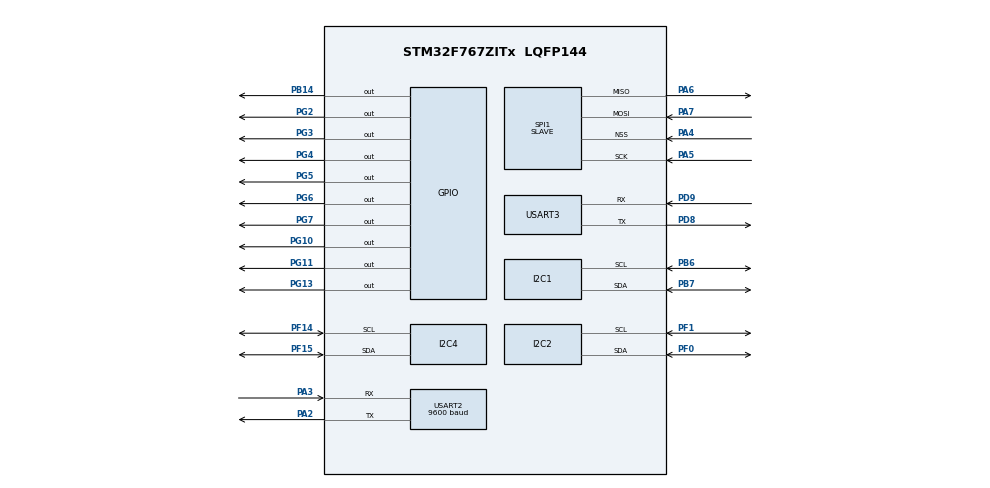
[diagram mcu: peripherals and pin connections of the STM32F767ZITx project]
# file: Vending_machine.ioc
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Mcu.Family=STM32F7
PA6.Mode=Full_Duplex_Slave
Dma.SPI1_TX.0.MemInc=DMA_MINC_ENABLE
Dma.SPI1_TX.0.PeriphInc=DMA_PINC_DISABLE
Dma.SPI1_RX.1.Mode=DMA_CIRCULAR
PG6.Signal=GPIO_Output
Dma.SPI1_RX.1.FIFOMode=DMA_FIFOMODE_DISABLE
NVIC.I2C1_EV_IRQn=true\:0\:0\:false\:false\:true\:true\:true
SPI1.VirtualType=VM_SLAVE
Dma.I2C1_TX.2.PeriphDataAlignment=DMA_PDATAALIGN_BYTE
PG2.Signal=GPIO_Output
PG4.Signal=GPIO_Output
PB7.GPIO_FM7=__NULL
PC14/OSC32_IN.Mode=LSE-External-Oscillator
PG13.Signal=GPIO_Output
PD9.Mode=Asynchronous
PG11.Signal=GPIO_Output
ProjectManager.StackSize=0x400
USART3.VirtualMode-Asynchronous=VM_ASYNC
SPI1.CLKPolarity=SPI_POLARITY_LOW
PA4.Mode=NSS_Signal_Hard_Input
Dma.SPI1_RX.1.PeriphInc=DMA_PINC_DISABLE
SPI1.Direction=SPI_DIRECTION_2LINES
PG11.GPIO_PuPd=GPIO_PULLDOWN
PH0/OSC_IN.Mode=HSE-External-Oscillator
PB6.Signal=I2C1_SCL
PB6.Mode=I2C
PH1/OSC_OUT.Signal=RCC_OSC_OUT
PD8.Signal=USART3_TX
NVIC.DMA2_Stream0_IRQn=true\:0\:0\:false\:false\:true\:false\:true
Dma.I2C1_TX.2.MemDataAlignment=DMA_MDATAALIGN_BYTE
RCC.HSE_VALUE=25000000
Dma.SPI1_RX.1.Priority=DMA_PRIORITY_LOW
USART2.VirtualMode-Asynchronous=VM_ASYNC
PG13.GPIO_PuPd=GPIO_PULLDOWN
SPI1.DataSize=SPI_DATASIZE_8BIT
PB7.Signal=I2C1_SDA
SPI1.VirtualNSS=VM_NSSHARD
PF1.GPIO_Speed=GPIO_SPEED_FREQ_HIGH
NVIC.I2C1_ER_IRQn=true\:0\:0\:false\:false\:true\:true\:true
PH1/OSC_OUT.Mode=HSE-External-Oscillator
Dma.SPI1_RX.1.Direction=DMA_PERIPH_TO_MEMORY
PF15.Mode=I2C
Dma.SPI1_TX.0.Mode=DMA_CIRCULAR
Mcu.Package=LQFP144
PA6.Signal=SPI1_MISO
PC14/OSC32_IN.Signal=RCC_OSC32_IN
PB6.GPIO_FM6=__NULL
Dma.I2C1_TX.2.Instance=DMA1_Stream6
Dma.Request2=I2C1_TX
PF14.Signal=I2C4_SCL
Dma.Request1=SPI1_RX
PF0.Signal=I2C2_SDA
Dma.Request0=SPI1_TX
NVIC.DMA1_Stream6_IRQn=true\:0\:0\:false\:false\:true\:false\:true
Dma.I2C1_TX.2.FIFOMode=DMA_FIFOMODE_DISABLE
Dma.SPI1_RX.1.MemInc=DMA_MINC_ENABLE
Dma.I2C1_TX.2.Direction=DMA_MEMORY_TO_PERIPH
PA3.Signal=USART2_RX
PA5.Mode=Full_Duplex_Slave
PB7.GPIO_Speed=GPIO_SPEED_FREQ_LOW
Dma.SPI1_RX.1.Instance=DMA2_Stream0
I2C1.Speed=25
Dma.I2C1_TX.2.Mode=DMA_NORMAL
PA7.Mode=Full_Duplex_Slave
PG7.Signal=GPIO_Output
PG3.Signal=GPIO_Output
PG5.Signal=GPIO_Output
Dma.SPI1_RX.1.MemDataAlignment=DMA_MDATAALIGN_BYTE
PD9.Signal=USART3_RX
SPI1.CLKPhase=SPI_PHASE_1EDGE
USART2.BaudRate=9600
PG10.Signal=GPIO_Output
PF0.GPIO_Speed=GPIO_SPEED_FREQ_HIGH
PA3.Mode=Asynchronous
PF1.Mode=I2C
Dma.SPI1_TX.0.FIFOMode=DMA_FIFOMODE_DISABLE
ProjectManager.TargetToolchain=STM32CubeIDE
Dma.I2C1_TX.2.Priority=DMA_PRIORITY_HIGH
Dma.SPI1_TX.0.PeriphDataAlignment=DMA_PDATAALIGN_BYTE
Dma.SPI1_TX.0.Direction=DMA_MEMORY_TO_PERIPH
I2C1.Timing=0x10107BC0
NVIC.I2C2_ER_IRQn=true\:0\:0\:false\:false\:true\:true\:true
RCC.USBFreq_Value=96000000
NVIC.DMA2_Stream3_IRQn=true\:0\:0\:false\:false\:true\:false\:true
PD8.Mode=Asynchronous
PB14.Signal=GPIO_Output
PA5.Signal=SPI1_SCK
board=custom
RCC.VCOOutputFreq_Value=192000000
NVIC.SPI1_IRQn=true\:0\:0\:false\:false\:true\:true\:true
PH0/OSC_IN.Signal=RCC_OSC_IN
SPI1.Mode=SPI_MODE_SLAVE
PF14.Mode=I2C
Dma.I2C1_TX.2.MemInc=DMA_MINC_ENABLE
Dma.SPI1_TX.0.Instance=DMA2_Stream3
PF15.Signal=I2C4_SDA
PF1.Signal=I2C2_SCL
Mcu.Name=STM32F767ZITx
PA2.Signal=USART2_TX
I2C1.OwnAddress=0
Dma.SPI1_RX.1.PeriphDataAlignment=DMA_PDATAALIGN_BYTE
PA4.Signal=SPI1_NSS
PC15/OSC32_OUT.Mode=LSE-External-Oscillator
PB7.Mode=I2C
Dma.I2C1_TX.2.PeriphInc=DMA_PINC_DISABLE
ProjectManager.HeapSize=0x200
PF0.Mode=I2C
Dma.SPI1_TX.0.MemDataAlignment=DMA_MDATAALIGN_BYTE
Dma.SPI1_TX.0.Priority=DMA_PRIORITY_LOW
NVIC.I2C2_EV_IRQn=true\:0\:0\:false\:false\:true\:true\:true
RCC.HSI_VALUE=16000000
NVIC.PriorityGroup=NVIC_PRIORITYGROUP_4
PA2.Mode=Asynchronous
PC15/OSC32_OUT.Signal=RCC_OSC32_OUT
PB6.GPIO_Speed=GPIO_SPEED_FREQ_LOW
PA7.Signal=SPI1_MOSI

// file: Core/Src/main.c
/* USER CODE BEGIN Header */
/**
  ******************************************************************************
  * @file           : main.c
  * @brief          : Main program body
  ******************************************************************************
  * @attention
  *
  * <h2><center>&copy; Copyright (c) 2024 STMicroelectronics.
  * All rights reserved.</center></h2>
  *
  * This software component is licensed by ST under BSD 3-Clause license,
  * the "License"; You may not use this file except in compliance with the
  * License. You may obtain a copy of the License at:
  *                        opensource.org/licenses/BSD-3-Clause
  *
  ******************************************************************************
  */
/* USER CODE END Header */
#include "main.h"

/* USER CODE BEGIN Includes */
//#include "usart.h"
//#include "spi.h"
#include "application.h"  /* Our application logic (external prototypes, globals) */
#include <stdarg.h>
#include <stdio.h>
#include <string.h>
#include <stdbool.h>
/* USER CODE END Includes */

/* USER CODE BEGIN PD */
#define SPI_BUFFER_SIZE 6
/* USER CODE END PD */

I2C_HandleTypeDef hi2c1;
I2C_HandleTypeDef hi2c2;
I2C_HandleTypeDef hi2c4;
DMA_HandleTypeDef hdma_i2c1_tx;

SPI_HandleTypeDef hspi1;
DMA_HandleTypeDef hdma_spi1_tx;
DMA_HandleTypeDef hdma_spi1_rx;

UART_HandleTypeDef huart2;
UART_HandleTypeDef huart3;

void SystemClock_Config(void);
static void MX_GPIO_Init(void);
static void MX_DMA_Init(void);
static void MX_SPI1_Init(void);
static void MX_USART3_UART_Init(void);
static void MX_I2C1_Init(void);
static void MX_I2C4_Init(void);
static void MX_I2C2_Init(void);
static void MX_USART2_UART_Init(void);

int main(void)
{

  /* MCU Configuration--------------------------------------------------------*/

  /* Reset of all peripherals, Initializes the Flash interface and the Systick. */
  HAL_Init();

  /* Configure the system clock */
  SystemClock_Config();

  /* Initialize all configured peripherals */
  MX_GPIO_Init();
  MX_DMA_Init();
  MX_SPI1_Init();
  MX_USART3_UART_Init();
  MX_I2C1_Init();
  MX_I2C4_Init();
  MX_I2C2_Init();
  MX_USART2_UART_Init();
  /* USER CODE BEGIN 2 */
  init_application();
  /* USER CODE END 2 */

  /* Infinite loop */
  while (1) {

    /* USER CODE BEGIN 3 */
	loop_application();

  }
  /* USER CODE END 3 */
}

void SystemClock_Config(void)
{
  RCC_OscInitTypeDef RCC_OscInitStruct = {0};
  RCC_ClkInitTypeDef RCC_ClkInitStruct = {0};
  RCC_PeriphCLKInitTypeDef PeriphClkInitStruct = {0};

  /** Configure LSE Drive Capability
  */
  HAL_PWR_EnableBkUpAccess();
  /** Configure the main internal regulator output voltage
  */
  __HAL_RCC_PWR_CLK_ENABLE();
  __HAL_PWR_VOLTAGESCALING_CONFIG(PWR_REGULATOR_VOLTAGE_SCALE3);
  /** Initializes the RCC Oscillators according to the specified parameters
  * in the RCC_OscInitTypeDef structure.
  */
  RCC_OscInitStruct.OscillatorType = RCC_OSCILLATORTYPE_HSI;
  RCC_OscInitStruct.HSIState = RCC_HSI_ON;
  RCC_OscInitStruct.HSICalibrationValue = RCC_HSICALIBRATION_DEFAULT;
  RCC_OscInitStruct.PLL.PLLState = RCC_PLL_NONE;
  if (HAL_RCC_OscConfig(&RCC_OscInitStruct) != HAL_OK)
  {
    Error_Handler();
  }
  /** Initializes the CPU, AHB and APB buses clocks
  */
  RCC_ClkInitStruct.ClockType = RCC_CLOCKTYPE_HCLK|RCC_CLOCKTYPE_SYSCLK
                              |RCC_CLOCKTYPE_PCLK1|RCC_CLOCKTYPE_PCLK2;
  RCC_ClkInitStruct.SYSCLKSource = RCC_SYSCLKSOURCE_HSI;
  RCC_ClkInitStruct.AHBCLKDivider = RCC_SYSCLK_DIV1;
  RCC_ClkInitStruct.APB1CLKDivider = RCC_HCLK_DIV1;
  RCC_ClkInitStruct.APB2CLKDivider = RCC_HCLK_DIV1;

  if (HAL_RCC_ClockConfig(&RCC_ClkInitStruct, FLASH_LATENCY_0) != HAL_OK)
  {
    Error_Handler();
  }
  PeriphClkInitStruct.PeriphClockSelection = RCC_PERIPHCLK_USART2|RCC_PERIPHCLK_USART3
                              |RCC_PERIPHCLK_I2C1|RCC_PERIPHCLK_I2C2
                              |RCC_PERIPHCLK_I2C4;
  PeriphClkInitStruct.Usart2ClockSelection = RCC_USART2CLKSOURCE_PCLK1;
  PeriphClkInitStruct.Usart3ClockSelection = RCC_USART3CLKSOURCE_PCLK1;
  PeriphClkInitStruct.I2c1ClockSelection = RCC_I2C1CLKSOURCE_PCLK1;
  PeriphClkInitStruct.I2c2ClockSelection = RCC_I2C2CLKSOURCE_PCLK1;
  PeriphClkInitStruct.I2c4ClockSelection = RCC_I2C4CLKSOURCE_PCLK1;
  if (HAL_RCCEx_PeriphCLKConfig(&PeriphClkInitStruct) != HAL_OK)
  {
    Error_Handler();
  }
}

static void MX_I2C1_Init(void)
{

  hi2c1.Instance = I2C1;
  hi2c1.Init.Timing = 0x10107BC0;
  hi2c1.Init.OwnAddress1 = 0;
  hi2c1.Init.AddressingMode = I2C_ADDRESSINGMODE_7BIT;
  hi2c1.Init.DualAddressMode = I2C_DUALADDRESS_DISABLE;
  hi2c1.Init.OwnAddress2 = 0;
  hi2c1.Init.OwnAddress2Masks = I2C_OA2_NOMASK;
  hi2c1.Init.GeneralCallMode = I2C_GENERALCALL_DISABLE;
  hi2c1.Init.NoStretchMode = I2C_NOSTRETCH_DISABLE;
  if (HAL_I2C_Init(&hi2c1) != HAL_OK)
  {
    Error_Handler();
  }
  /** Configure Analogue filter
  */
  if (HAL_I2CEx_ConfigAnalogFilter(&hi2c1, I2C_ANALOGFILTER_ENABLE) != HAL_OK)
  {
    Error_Handler();
  }
  /** Configure Digital filter
  */
  if (HAL_I2CEx_ConfigDigitalFilter(&hi2c1, 0) != HAL_OK)
  {
    Error_Handler();
  }
  /* USER CODE BEGIN I2C1_Init 2 */
  //__HAL_LINKDMA(&hi2c1, hdmatx, hdma_i2c1_tx);

  /* USER CODE END I2C1_Init 2 */

}

static void MX_I2C2_Init(void)
{

  hi2c2.Instance = I2C2;
  hi2c2.Init.Timing = 0x00303D5B;
  hi2c2.Init.OwnAddress1 = 0;
  hi2c2.Init.AddressingMode = I2C_ADDRESSINGMODE_7BIT;
  hi2c2.Init.DualAddressMode = I2C_DUALADDRESS_DISABLE;
  hi2c2.Init.OwnAddress2 = 0;
  hi2c2.Init.OwnAddress2Masks = I2C_OA2_NOMASK;
  hi2c2.Init.GeneralCallMode = I2C_GENERALCALL_DISABLE;
  hi2c2.Init.NoStretchMode = I2C_NOSTRETCH_DISABLE;
  if (HAL_I2C_Init(&hi2c2) != HAL_OK)
  {
    Error_Handler();
  }
  /** Configure Analogue filter
  */
  if (HAL_I2CEx_ConfigAnalogFilter(&hi2c2, I2C_ANALOGFILTER_ENABLE) != HAL_OK)
  {
    Error_Handler();
  }
  /** Configure Digital filter
  */
  if (HAL_I2CEx_ConfigDigitalFilter(&hi2c2, 0) != HAL_OK)
  {
    Error_Handler();
  }

}

static void MX_I2C4_Init(void)
{

  hi2c4.Instance = I2C4;
  hi2c4.Init.Timing = 0x00303D5B;
  hi2c4.Init.OwnAddress1 = 0;
  hi2c4.Init.AddressingMode = I2C_ADDRESSINGMODE_7BIT;
  hi2c4.Init.DualAddressMode = I2C_DUALADDRESS_DISABLE;
  hi2c4.Init.OwnAddress2 = 0;
  hi2c4.Init.OwnAddress2Masks = I2C_OA2_NOMASK;
  hi2c4.Init.GeneralCallMode = I2C_GENERALCALL_DISABLE;
  hi2c4.Init.NoStretchMode = I2C_NOSTRETCH_DISABLE;
  if (HAL_I2C_Init(&hi2c4) != HAL_OK)
  {
    Error_Handler();
  }
  /** Configure Analogue filter
  */
  if (HAL_I2CEx_ConfigAnalogFilter(&hi2c4, I2C_ANALOGFILTER_ENABLE) != HAL_OK)
  {
    Error_Handler();
  }
  /** Configure Digital filter
  */
  if (HAL_I2CEx_ConfigDigitalFilter(&hi2c4, 0) != HAL_OK)
  {
    Error_Handler();
  }

}

static void MX_SPI1_Init(void)
{

  /* SPI1 parameter configuration*/
  hspi1.Instance = SPI1;
  hspi1.Init.Mode = SPI_MODE_SLAVE;
  hspi1.Init.Direction = SPI_DIRECTION_2LINES;
  hspi1.Init.DataSize = SPI_DATASIZE_8BIT;
  hspi1.Init.CLKPolarity = SPI_POLARITY_LOW;
  hspi1.Init.CLKPhase = SPI_PHASE_1EDGE;
  hspi1.Init.NSS = SPI_NSS_HARD_INPUT;
  hspi1.Init.FirstBit = SPI_FIRSTBIT_MSB;
  hspi1.Init.TIMode = SPI_TIMODE_DISABLE;
  hspi1.Init.CRCCalculation = SPI_CRCCALCULATION_DISABLE;
  hspi1.Init.CRCPolynomial = 7;
  hspi1.Init.CRCLength = SPI_CRC_LENGTH_DATASIZE;
  hspi1.Init.NSSPMode = SPI_NSS_PULSE_DISABLE;
  if (HAL_SPI_Init(&hspi1) != HAL_OK)
  {
    Error_Handler();
  }

}

static void MX_USART2_UART_Init(void)
{

  huart2.Instance = USART2;
  huart2.Init.BaudRate = 9600;
  huart2.Init.WordLength = UART_WORDLENGTH_8B;
  huart2.Init.StopBits = UART_STOPBITS_1;
  huart2.Init.Parity = UART_PARITY_NONE;
  huart2.Init.Mode = UART_MODE_TX_RX;
  huart2.Init.HwFlowCtl = UART_HWCONTROL_NONE;
  huart2.Init.OverSampling = UART_OVERSAMPLING_16;
  huart2.Init.OneBitSampling = UART_ONE_BIT_SAMPLE_DISABLE;
  huart2.AdvancedInit.AdvFeatureInit = UART_ADVFEATURE_NO_INIT;
  if (HAL_UART_Init(&huart2) != HAL_OK)
  {
    Error_Handler();
  }

}

static void MX_USART3_UART_Init(void)
{

  huart3.Instance = USART3;
  huart3.Init.BaudRate = 115200;
  huart3.Init.WordLength = UART_WORDLENGTH_8B;
  huart3.Init.StopBits = UART_STOPBITS_1;
  huart3.Init.Parity = UART_PARITY_NONE;
  huart3.Init.Mode = UART_MODE_TX_RX;
  huart3.Init.HwFlowCtl = UART_HWCONTROL_NONE;
  huart3.Init.OverSampling = UART_OVERSAMPLING_16;
  huart3.Init.OneBitSampling = UART_ONE_BIT_SAMPLE_DISABLE;
  huart3.AdvancedInit.AdvFeatureInit = UART_ADVFEATURE_NO_INIT;
  if (HAL_UART_Init(&huart3) != HAL_OK)
  {
    Error_Handler();
  }

}

static void MX_DMA_Init(void)
{

  /* DMA controller clock enable */
  __HAL_RCC_DMA2_CLK_ENABLE();
  __HAL_RCC_DMA1_CLK_ENABLE();

  /* DMA interrupt init */
  /* DMA1_Stream6_IRQn interrupt configuration */
  HAL_NVIC_SetPriority(DMA1_Stream6_IRQn, 0, 0);
  HAL_NVIC_EnableIRQ(DMA1_Stream6_IRQn);
  /* DMA2_Stream0_IRQn interrupt configuration */
  HAL_NVIC_SetPriority(DMA2_Stream0_IRQn, 0, 0);
  HAL_NVIC_EnableIRQ(DMA2_Stream0_IRQn);
  /* DMA2_Stream3_IRQn interrupt configuration */
  HAL_NVIC_SetPriority(DMA2_Stream3_IRQn, 0, 0);
  HAL_NVIC_EnableIRQ(DMA2_Stream3_IRQn);

}

static void MX_GPIO_Init(void)
{
  GPIO_InitTypeDef GPIO_InitStruct = {0};

  /* GPIO Ports Clock Enable */
  __HAL_RCC_GPIOC_CLK_ENABLE();
  __HAL_RCC_GPIOF_CLK_ENABLE();
  __HAL_RCC_GPIOH_CLK_ENABLE();
  __HAL_RCC_GPIOA_CLK_ENABLE();
  __HAL_RCC_GPIOB_CLK_ENABLE();
  __HAL_RCC_GPIOD_CLK_ENABLE();
  __HAL_RCC_GPIOG_CLK_ENABLE();

  /*Configure GPIO pin Output Level */
  HAL_GPIO_WritePin(GPIOB, GPIO_PIN_14, GPIO_PIN_RESET);

  /*Configure GPIO pin Output Level */
  HAL_GPIO_WritePin(GPIOG, GPIO_PIN_2|GPIO_PIN_3|GPIO_PIN_4|GPIO_PIN_5
                          |GPIO_PIN_6|GPIO_PIN_7|GPIO_PIN_10|GPIO_PIN_11
                          |GPIO_PIN_13, GPIO_PIN_RESET);

  /*Configure GPIO pin : PB14 */
  GPIO_InitStruct.Pin = GPIO_PIN_14;
  GPIO_InitStruct.Mode = GPIO_MODE_OUTPUT_PP;
  GPIO_InitStruct.Pull = GPIO_NOPULL;
  GPIO_InitStruct.Speed = GPIO_SPEED_FREQ_LOW;
  HAL_GPIO_Init(GPIOB, &GPIO_InitStruct);

  /*Configure GPIO pins : PG2 PG3 PG4 PG5
                           PG6 PG7 PG10 */
  GPIO_InitStruct.Pin = GPIO_PIN_2|GPIO_PIN_3|GPIO_PIN_4|GPIO_PIN_5
                          |GPIO_PIN_6|GPIO_PIN_7|GPIO_PIN_10;
  GPIO_InitStruct.Mode = GPIO_MODE_OUTPUT_PP;
  GPIO_InitStruct.Pull = GPIO_NOPULL;
  GPIO_InitStruct.Speed = GPIO_SPEED_FREQ_LOW;
  HAL_GPIO_Init(GPIOG, &GPIO_InitStruct);

  /*Configure GPIO pins : PG11 PG13 */
  GPIO_InitStruct.Pin = GPIO_PIN_11|GPIO_PIN_13;
  GPIO_InitStruct.Mode = GPIO_MODE_OUTPUT_PP;
  GPIO_InitStruct.Pull = GPIO_PULLDOWN;
  GPIO_InitStruct.Speed = GPIO_SPEED_FREQ_LOW;
  HAL_GPIO_Init(GPIOG, &GPIO_InitStruct);

}

void Error_Handler(void)
{
  /* USER CODE BEGIN Error_Handler_Debug */
  __disable_irq();
  while (1) {
    // Stay here
  }
  /* USER CODE END Error_Handler_Debug */
}

/************************ (C) COPYRIGHT STMicroelectronics *****END OF FILE****/
